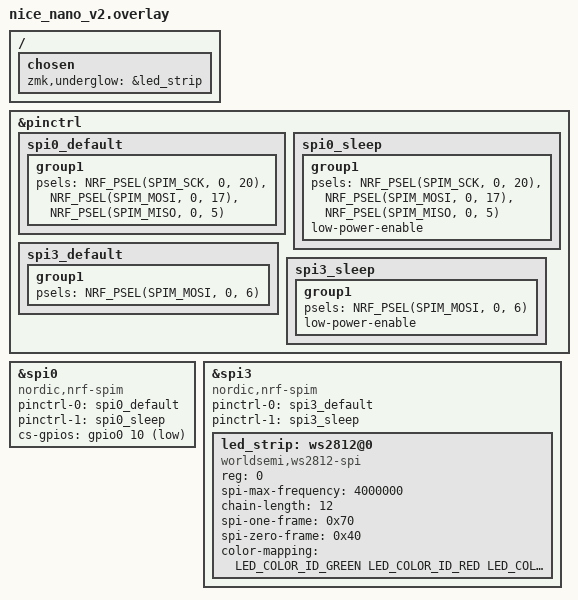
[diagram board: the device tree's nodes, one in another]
#include <dt-bindings/led/led.h>

&pinctrl {
    spi0_default: spi0_default {
        group1 {
            psels = <NRF_PSEL(SPIM_SCK, 0, 20)>,
                <NRF_PSEL(SPIM_MOSI, 0, 17)>,
                <NRF_PSEL(SPIM_MISO, 0, 5)>;
        };
    };

    spi0_sleep: spi0_sleep {
        group1 {
            psels = <NRF_PSEL(SPIM_SCK, 0, 20)>,
                <NRF_PSEL(SPIM_MOSI, 0, 17)>,
                <NRF_PSEL(SPIM_MISO, 0, 5)>;
            low-power-enable;
        };
    };

    spi3_default: spi3_default {
        group1 {
            psels = <NRF_PSEL(SPIM_MOSI, 0, 6)>; // WS2812_VEXT_DATA
        };
    };

    spi3_sleep: spi3_sleep {
        group1 {
            psels = <NRF_PSEL(SPIM_MOSI, 0, 6)>;
            low-power-enable;
        };
    };
};

&spi0 {
    status = "okay";
    compatible = "nordic,nrf-spim";
    pinctrl-0 = <&spi0_default>;
    pinctrl-1 = <&spi0_sleep>;
    pinctrl-names = "default", "sleep";
    cs-gpios = <&gpio0 10 GPIO_ACTIVE_LOW>;
};

&spi3 {
    compatible = "nordic,nrf-spim";
    status = "okay";

    pinctrl-0 = <&spi3_default>;
    pinctrl-1 = <&spi3_sleep>;
    pinctrl-names = "default", "sleep";

    led_strip: ws2812@0 {
        compatible = "worldsemi,ws2812-spi";

        /* SPI */
        reg = <0>; /* ignored, but necessary for SPI bindings */
        spi-max-frequency = <4000000>;

        /* WS2812 */
        chain-length = <12>; /* 40 keys have underglow at the moment */
        spi-one-frame = <0x70>;
        spi-zero-frame = <0x40>;

        color-mapping = <LED_COLOR_ID_GREEN LED_COLOR_ID_RED LED_COLOR_ID_BLUE>;
    };
};

/{
    chosen {
        zmk,underglow = &led_strip;
    };
};
